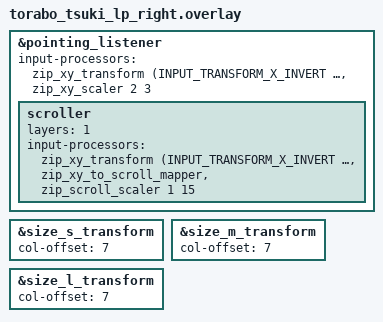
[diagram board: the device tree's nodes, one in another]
#define TORABO_TSUKI_LP_RIGHT 1

#include "torabo_tsuki_lp.dtsi"
#include <input/processors.dtsi>
#include <dt-bindings/zmk/input_transform.h>

&pointing_listener {
    // zip_xy_scaler <multiplier> <divisor> : trackball speed = multiplier/divisor
    input-processors = <&zip_xy_transform (INPUT_TRANSFORM_X_INVERT | INPUT_TRANSFORM_Y_INVERT)>,
                        <&zip_xy_scaler 2 3>;

    // layer_1: trackball moves act as scroll instead of cursor movement
    // zip_scroll_scaler <multiplier> <divisor> : scroll speed = multiplier/divisor
    scroller {
        layers = <1>;
        input-processors = <&zip_xy_transform (INPUT_TRANSFORM_X_INVERT | INPUT_TRANSFORM_Y_INVERT)>,
                            <&zip_xy_to_scroll_mapper>,
                            <&zip_scroll_scaler 1 15>;
    };
};

&size_s_transform {
    col-offset = <7>;
};

&size_m_transform {
    col-offset = <7>;
};

&size_l_transform {
    col-offset = <7>;
};
